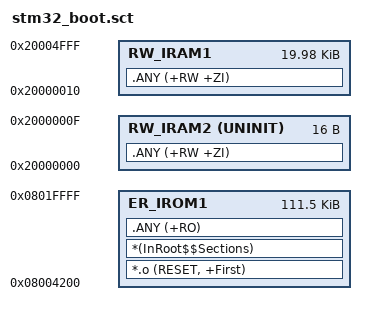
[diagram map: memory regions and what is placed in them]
; *************************************************************
; *** Scatter-Loading Description File generated by uVision ***
; *************************************************************

LR_IROM1 0x08004200 0x0001BE00  {    ; load region size_region
  ER_IROM1 0x08004200 0x0001BE00  {  ; load address = execution address
   *.o (RESET, +First)
   *(InRoot$$Sections)
   .ANY (+RO)
  }
  RW_IRAM1 0x20000010 0x00004FF0  {  ; RW data
   .ANY (+RW +ZI)
  }
  RW_IRAM2 0x20000000 UNINIT 0x00000010  {
   .ANY (+RW +ZI)
  }
}

